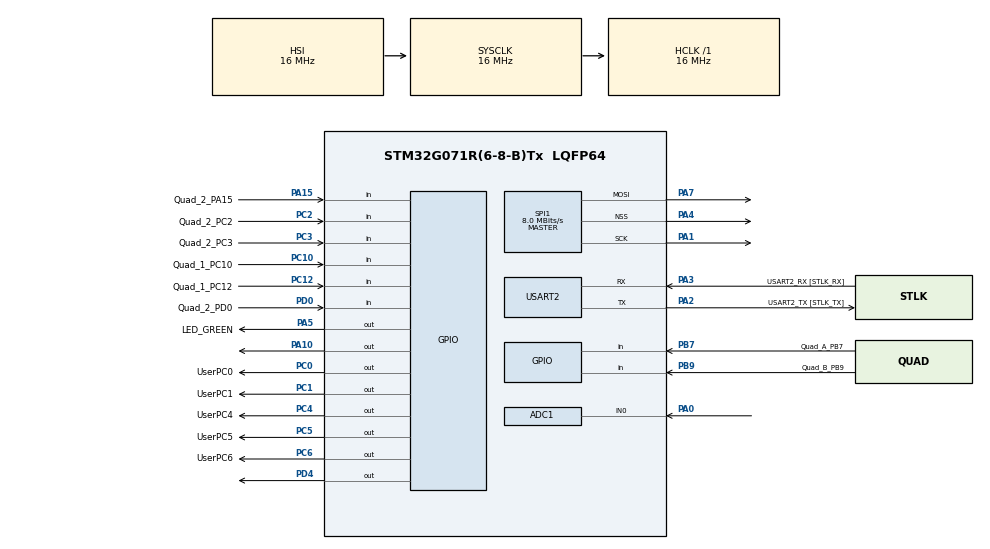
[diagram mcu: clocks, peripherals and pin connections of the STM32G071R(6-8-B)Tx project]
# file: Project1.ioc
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ADC1.Channel-0\#ChannelRegularConversion=ADC_CHANNEL_0
ADC1.NbrOfConversionFlag=1
ADC1.Rank-0\#ChannelRegularConversion=1
ADC1.SamplingTime-0\#ChannelRegularConversion=ADC_SAMPLINGTIME_COMMON_1
ADC1.SelectedChannel=ADC_CHANNEL_0
ADC1.master=1
Mcu.Family=STM32G0
Mcu.Name=STM32G071R(6-8-B)Tx
Mcu.Package=LQFP64
NVIC.TIM16_IRQn=true\:0\:0\:false\:false\:true\:true\:true\:true
NVIC.TIM17_IRQn=true\:0\:0\:false\:false\:true\:true\:true\:true
PA0.Mode=IN0
PA0.Signal=ADC1_IN0
PA1.Mode=TX_Only_Simplex_Unidirect_Master
PA1.Signal=SPI1_SCK
PA10.Signal=GPIO_Output
PA13.GPIO_Label=TMS
PA13.Mode=Serial_Wire
PA13.Signal=SYS_SWDIO
PA14-BOOT0.Mode=Serial_Wire
PA14-BOOT0.Signal=SYS_SWCLK
PA15.GPIO_Label=Quad_2_PA15
PA15.Signal=GPIO_Input
PA2.GPIO_Label=USART2_TX [STLK_TX]
PA2.GPIO_PuPd=GPIO_PULLUP
PA2.Mode=Asynchronous
PA2.Signal=USART2_TX
PA3.GPIO_Label=USART2_RX [STLK_RX]
PA3.GPIO_PuPd=GPIO_PULLUP
PA3.Mode=Asynchronous
PA3.Signal=USART2_RX
PA4.Mode=NSS_Signal_Hard_Output
PA4.Signal=SPI1_NSS
PA5.GPIO_Label=LED_GREEN
PA5.GPIO_Speed=GPIO_SPEED_FREQ_HIGH
PA5.Signal=GPIO_Output
PA7.Mode=TX_Only_Simplex_Unidirect_Master
PA7.Signal=SPI1_MOSI
PB7.GPIO_Label=Quad_A_PB7
PB7.GPIO_PuPd=GPIO_PULLUP
PB7.Signal=GPIO_Input
PB9.GPIO_Label=Quad_B_PB9
PB9.GPIO_PuPd=GPIO_PULLUP
PB9.Signal=GPIO_Input
PC0.GPIO_Label=UserPC0
PC0.Signal=GPIO_Output
PC1.GPIO_Label=UserPC1
PC1.Signal=GPIO_Output
PC10.GPIO_Label=Quad_1_PC10
PC10.GPIO_PuPd=GPIO_PULLUP
PC10.Signal=GPIO_Input
PC12.GPIO_Label=Quad_1_PC12
PC12.GPIO_PuPd=GPIO_PULLUP
PC12.Signal=GPIO_Input
PC13.Mode=SYS_WakeUp1
PC13.Signal=SYS_WKUP2
PC14-OSC32_IN\ (PC14).Mode=LSE-External-Oscillator
PC14-OSC32_IN\ (PC14).Signal=RCC_OSC32_IN
PC15-OSC32_OUT\ (PC15).Mode=LSE-External-Oscillator
PC15-OSC32_OUT\ (PC15).Signal=RCC_OSC32_OUT
PC2.GPIO_Label=Quad_2_PC2
PC2.GPIO_PuPd=GPIO_PULLUP
PC2.Signal=GPIO_Input
PC3.GPIO_Label=Quad_2_PC3
PC3.GPIO_PuPd=GPIO_PULLUP
PC3.Signal=GPIO_Input
PC4.GPIO_Label=UserPC4
PC4.Signal=GPIO_Output
PC5.GPIO_Label=UserPC5
PC5.Signal=GPIO_Output
PC6.GPIO_Label=UserPC6
PC6.Signal=GPIO_Output
PD0.GPIO_Label=Quad_2_PD0
PD0.Signal=GPIO_Input
PD4.Signal=GPIO_Output
PF0-OSC_IN\ (PF0).GPIO_Label=MCO
PF0-OSC_IN\ (PF0).Mode=HSE-External-Clock-Source
PF0-OSC_IN\ (PF0).Signal=RCC_OSC_IN
ProjectManager.HeapSize=0x200
ProjectManager.StackSize=0x400
ProjectManager.TargetToolchain=STM32CubeIDE
RCC.AHBFreq_Value=16000000
RCC.CortexFreq_Value=16000000
RCC.EXTERNAL_CLOCK_VALUE=12288000
RCC.HCLKFreq_Value=16000000
RCC.HSE_VALUE=8000000
RCC.HSI_VALUE=16000000
RCC.SYSCLKFreq_VALUE=16000000
RCC.VCOOutputFreq_Value=128000000
SPI1.BaudRatePrescaler=SPI_BAUDRATEPRESCALER_2
SPI1.CalculateBaudRate=8.0 MBits/s
SPI1.DataSize=SPI_DATASIZE_8BIT
SPI1.Direction=SPI_DIRECTION_2LINES
SPI1.Mode=SPI_MODE_MASTER
SPI1.VirtualNSS=VM_NSSHARD
SPI1.VirtualType=VM_MASTER
TIM16.Period=199
TIM16.Prescaler=2
TIM17.Period=7999
TIM17.Prescaler=1
USART2.VirtualMode-Asynchronous=VM_ASYNC
VP_TIM16_VS_ClockSourceINT.Mode=Enable_Timer
VP_TIM17_VS_ClockSourceINT.Mode=Enable_Timer
board=NUCLEO-G071RB

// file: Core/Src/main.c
/* USER CODE BEGIN Header */
/**
  ******************************************************************************
  * @file           : main.c
  * @brief          : Main program body
  ******************************************************************************
  * @attention
  *
  * Copyright (c) 2023 STMicroelectronics.
  * All rights reserved.
  *
  * This software is licensed under terms that can be found in the LICENSE file
  * in the root directory of this software component.
  * If no LICENSE file comes with this software, it is provided AS-IS.
  *
  ******************************************************************************
  */
/* USER CODE END Header */
#include "main.h"

/* USER CODE BEGIN Includes */
#include "cpp_main.h"
/* USER CODE END Includes */

ADC_HandleTypeDef hadc1;

SPI_HandleTypeDef hspi1;

TIM_HandleTypeDef htim16;
TIM_HandleTypeDef htim17;

UART_HandleTypeDef huart2;

void SystemClock_Config(void);
static void MX_GPIO_Init(void);
static void MX_USART2_UART_Init(void);
static void MX_TIM17_Init(void);
static void MX_ADC1_Init(void);
static void MX_TIM16_Init(void);
static void MX_SPI1_Init(void);

/* USER CODE BEGIN 0 */
//void HAL_TIM_PeriodElapsedCallback(TIM_HandleTypeDef *htim17){};

/* USER CODE END 0 */

int main(void)
{

  /* MCU Configuration--------------------------------------------------------*/

  /* Reset of all peripherals, Initializes the Flash interface and the Systick. */
  HAL_Init();

  /* Configure the system clock */
  SystemClock_Config();

  /* Initialize all configured peripherals */
  MX_GPIO_Init();
  MX_USART2_UART_Init();
  MX_TIM17_Init();
  MX_ADC1_Init();
  MX_TIM16_Init();
  MX_SPI1_Init();
  /* USER CODE BEGIN 2 */
  MX_TIM17_Init();

  /* USER CODE BEGIN 2 */
  /******************** Really Sean's code
  *********************/
  /*** Refers to "private variable" in line 43 symbol =
  htim17) ***/
  /*** Uses an ARM CMSIS function in the HAL framework
  ***/
  /*** Start the periodic timer now, immediately after
  init() ***/
  HAL_TIM_Base_Start_IT(&htim17);
  /*** Also initialize my knob-debounce FSM object, my
  queue ***/
  /*** object and my sample-timing object.
  ***/

  HAL_TIM_Base_Start_IT(&htim16);
  //HAL_ADC_Start_IT(&hadc1);

  /* USER CODE END 2 */

  /* Infinite loop */
  /* USER CODE BEGIN WHILE */
  do_cpp_loop();

  while (1)
  {
    /* USER CODE END WHILE */

  }
}

void SystemClock_Config(void)
{
  RCC_OscInitTypeDef RCC_OscInitStruct = {0};
  RCC_ClkInitTypeDef RCC_ClkInitStruct = {0};

  /** Configure the main internal regulator output voltage
  */
  HAL_PWREx_ControlVoltageScaling(PWR_REGULATOR_VOLTAGE_SCALE1);

  /** Initializes the RCC Oscillators according to the specified parameters
  * in the RCC_OscInitTypeDef structure.
  */
  RCC_OscInitStruct.OscillatorType = RCC_OSCILLATORTYPE_HSI;
  RCC_OscInitStruct.HSIState = RCC_HSI_ON;
  RCC_OscInitStruct.HSIDiv = RCC_HSI_DIV1;
  RCC_OscInitStruct.HSICalibrationValue = RCC_HSICALIBRATION_DEFAULT;
  RCC_OscInitStruct.PLL.PLLState = RCC_PLL_NONE;
  if (HAL_RCC_OscConfig(&RCC_OscInitStruct) != HAL_OK)
  {
    Error_Handler();
  }

  /** Initializes the CPU, AHB and APB buses clocks
  */
  RCC_ClkInitStruct.ClockType = RCC_CLOCKTYPE_HCLK|RCC_CLOCKTYPE_SYSCLK
                              |RCC_CLOCKTYPE_PCLK1;
  RCC_ClkInitStruct.SYSCLKSource = RCC_SYSCLKSOURCE_HSI;
  RCC_ClkInitStruct.AHBCLKDivider = RCC_SYSCLK_DIV1;
  RCC_ClkInitStruct.APB1CLKDivider = RCC_HCLK_DIV1;

  if (HAL_RCC_ClockConfig(&RCC_ClkInitStruct, FLASH_LATENCY_0) != HAL_OK)
  {
    Error_Handler();
  }
}

static void MX_ADC1_Init(void)
{

  ADC_ChannelConfTypeDef sConfig = {0};

  /** Configure the global features of the ADC (Clock, Resolution, Data Alignment and number of conversion)
  */
  hadc1.Instance = ADC1;
  hadc1.Init.ClockPrescaler = ADC_CLOCK_SYNC_PCLK_DIV2;
  hadc1.Init.Resolution = ADC_RESOLUTION_12B;
  hadc1.Init.DataAlign = ADC_DATAALIGN_RIGHT;
  hadc1.Init.ScanConvMode = ADC_SCAN_DISABLE;
  hadc1.Init.EOCSelection = ADC_EOC_SINGLE_CONV;
  hadc1.Init.LowPowerAutoWait = DISABLE;
  hadc1.Init.LowPowerAutoPowerOff = DISABLE;
  hadc1.Init.ContinuousConvMode = DISABLE;
  hadc1.Init.NbrOfConversion = 1;
  hadc1.Init.DiscontinuousConvMode = DISABLE;
  hadc1.Init.ExternalTrigConv = ADC_SOFTWARE_START;
  hadc1.Init.ExternalTrigConvEdge = ADC_EXTERNALTRIGCONVEDGE_NONE;
  hadc1.Init.DMAContinuousRequests = DISABLE;
  hadc1.Init.Overrun = ADC_OVR_DATA_PRESERVED;
  hadc1.Init.SamplingTimeCommon1 = ADC_SAMPLETIME_1CYCLE_5;
  hadc1.Init.SamplingTimeCommon2 = ADC_SAMPLETIME_1CYCLE_5;
  hadc1.Init.OversamplingMode = DISABLE;
  hadc1.Init.TriggerFrequencyMode = ADC_TRIGGER_FREQ_HIGH;
  if (HAL_ADC_Init(&hadc1) != HAL_OK)
  {
    Error_Handler();
  }

  /** Configure Regular Channel
  */
  sConfig.Channel = ADC_CHANNEL_0;
  sConfig.Rank = ADC_REGULAR_RANK_1;
  sConfig.SamplingTime = ADC_SAMPLINGTIME_COMMON_1;
  if (HAL_ADC_ConfigChannel(&hadc1, &sConfig) != HAL_OK)
  {
    Error_Handler();
  }

}

static void MX_SPI1_Init(void)
{

  /* SPI1 parameter configuration*/
  hspi1.Instance = SPI1;
  hspi1.Init.Mode = SPI_MODE_MASTER;
  hspi1.Init.Direction = SPI_DIRECTION_2LINES;
  hspi1.Init.DataSize = SPI_DATASIZE_8BIT;
  hspi1.Init.CLKPolarity = SPI_POLARITY_LOW;
  hspi1.Init.CLKPhase = SPI_PHASE_1EDGE;
  hspi1.Init.NSS = SPI_NSS_HARD_OUTPUT;
  hspi1.Init.BaudRatePrescaler = SPI_BAUDRATEPRESCALER_2;
  hspi1.Init.FirstBit = SPI_FIRSTBIT_MSB;
  hspi1.Init.TIMode = SPI_TIMODE_DISABLE;
  hspi1.Init.CRCCalculation = SPI_CRCCALCULATION_DISABLE;
  hspi1.Init.CRCPolynomial = 7;
  hspi1.Init.CRCLength = SPI_CRC_LENGTH_DATASIZE;
  hspi1.Init.NSSPMode = SPI_NSS_PULSE_ENABLE;
  if (HAL_SPI_Init(&hspi1) != HAL_OK)
  {
    Error_Handler();
  }

}

static void MX_TIM16_Init(void)
{

  htim16.Instance = TIM16;
  htim16.Init.Prescaler = 2;
  htim16.Init.CounterMode = TIM_COUNTERMODE_UP;
  htim16.Init.Period = 199;
  htim16.Init.ClockDivision = TIM_CLOCKDIVISION_DIV1;
  htim16.Init.RepetitionCounter = 0;
  htim16.Init.AutoReloadPreload = TIM_AUTORELOAD_PRELOAD_DISABLE;
  if (HAL_TIM_Base_Init(&htim16) != HAL_OK)
  {
    Error_Handler();
  }

}

static void MX_TIM17_Init(void)
{

  htim17.Instance = TIM17;
  htim17.Init.Prescaler = 1;
  htim17.Init.CounterMode = TIM_COUNTERMODE_UP;
  htim17.Init.Period = 7999;
  htim17.Init.ClockDivision = TIM_CLOCKDIVISION_DIV1;
  htim17.Init.RepetitionCounter = 0;
  htim17.Init.AutoReloadPreload = TIM_AUTORELOAD_PRELOAD_DISABLE;
  if (HAL_TIM_Base_Init(&htim17) != HAL_OK)
  {
    Error_Handler();
  }

}

static void MX_USART2_UART_Init(void)
{

  huart2.Instance = USART2;
  huart2.Init.BaudRate = 115200;
  huart2.Init.WordLength = UART_WORDLENGTH_8B;
  huart2.Init.StopBits = UART_STOPBITS_1;
  huart2.Init.Parity = UART_PARITY_NONE;
  huart2.Init.Mode = UART_MODE_TX_RX;
  huart2.Init.HwFlowCtl = UART_HWCONTROL_NONE;
  huart2.Init.OverSampling = UART_OVERSAMPLING_16;
  huart2.Init.OneBitSampling = UART_ONE_BIT_SAMPLE_DISABLE;
  huart2.Init.ClockPrescaler = UART_PRESCALER_DIV1;
  huart2.AdvancedInit.AdvFeatureInit = UART_ADVFEATURE_NO_INIT;
  if (HAL_UART_Init(&huart2) != HAL_OK)
  {
    Error_Handler();
  }
  if (HAL_UARTEx_SetTxFifoThreshold(&huart2, UART_TXFIFO_THRESHOLD_1_8) != HAL_OK)
  {
    Error_Handler();
  }
  if (HAL_UARTEx_SetRxFifoThreshold(&huart2, UART_RXFIFO_THRESHOLD_1_8) != HAL_OK)
  {
    Error_Handler();
  }
  if (HAL_UARTEx_DisableFifoMode(&huart2) != HAL_OK)
  {
    Error_Handler();
  }

}

static void MX_GPIO_Init(void)
{
  GPIO_InitTypeDef GPIO_InitStruct = {0};

  /* GPIO Ports Clock Enable */
  __HAL_RCC_GPIOC_CLK_ENABLE();
  __HAL_RCC_GPIOF_CLK_ENABLE();
  __HAL_RCC_GPIOA_CLK_ENABLE();
  __HAL_RCC_GPIOD_CLK_ENABLE();
  __HAL_RCC_GPIOB_CLK_ENABLE();

  /*Configure GPIO pin Output Level */
  HAL_GPIO_WritePin(GPIOC, UserPC0_Pin|UserPC1_Pin|UserPC4_Pin|UserPC5_Pin
                          |UserPC6_Pin, GPIO_PIN_RESET);

  /*Configure GPIO pin Output Level */
  HAL_GPIO_WritePin(GPIOA, LED_GREEN_Pin|GPIO_PIN_10, GPIO_PIN_RESET);

  /*Configure GPIO pin Output Level */
  HAL_GPIO_WritePin(GPIOD, GPIO_PIN_4, GPIO_PIN_RESET);

  /*Configure GPIO pins : Quad_1_PC12_Pin Quad_2_PC2_Pin Quad_2_PC3_Pin Quad_1_PC10_Pin */
  GPIO_InitStruct.Pin = Quad_1_PC12_Pin|Quad_2_PC2_Pin|Quad_2_PC3_Pin|Quad_1_PC10_Pin;
  GPIO_InitStruct.Mode = GPIO_MODE_INPUT;
  GPIO_InitStruct.Pull = GPIO_PULLUP;
  HAL_GPIO_Init(GPIOC, &GPIO_InitStruct);

  /*Configure GPIO pins : UserPC0_Pin UserPC1_Pin UserPC4_Pin UserPC5_Pin
                           UserPC6_Pin */
  GPIO_InitStruct.Pin = UserPC0_Pin|UserPC1_Pin|UserPC4_Pin|UserPC5_Pin
                          |UserPC6_Pin;
  GPIO_InitStruct.Mode = GPIO_MODE_OUTPUT_PP;
  GPIO_InitStruct.Pull = GPIO_NOPULL;
  GPIO_InitStruct.Speed = GPIO_SPEED_FREQ_LOW;
  HAL_GPIO_Init(GPIOC, &GPIO_InitStruct);

  /*Configure GPIO pin : LED_GREEN_Pin */
  GPIO_InitStruct.Pin = LED_GREEN_Pin;
  GPIO_InitStruct.Mode = GPIO_MODE_OUTPUT_PP;
  GPIO_InitStruct.Pull = GPIO_NOPULL;
  GPIO_InitStruct.Speed = GPIO_SPEED_FREQ_HIGH;
  HAL_GPIO_Init(LED_GREEN_GPIO_Port, &GPIO_InitStruct);

  /*Configure GPIO pin : PA10 */
  GPIO_InitStruct.Pin = GPIO_PIN_10;
  GPIO_InitStruct.Mode = GPIO_MODE_OUTPUT_PP;
  GPIO_InitStruct.Pull = GPIO_NOPULL;
  GPIO_InitStruct.Speed = GPIO_SPEED_FREQ_LOW;
  HAL_GPIO_Init(GPIOA, &GPIO_InitStruct);

  /*Configure GPIO pin : Quad_2_PA15_Pin */
  GPIO_InitStruct.Pin = Quad_2_PA15_Pin;
  GPIO_InitStruct.Mode = GPIO_MODE_INPUT;
  GPIO_InitStruct.Pull = GPIO_NOPULL;
  HAL_GPIO_Init(Quad_2_PA15_GPIO_Port, &GPIO_InitStruct);

  /*Configure GPIO pin : Quad_2_PD0_Pin */
  GPIO_InitStruct.Pin = Quad_2_PD0_Pin;
  GPIO_InitStruct.Mode = GPIO_MODE_INPUT;
  GPIO_InitStruct.Pull = GPIO_NOPULL;
  HAL_GPIO_Init(Quad_2_PD0_GPIO_Port, &GPIO_InitStruct);

  /*Configure GPIO pin : PD4 */
  GPIO_InitStruct.Pin = GPIO_PIN_4;
  GPIO_InitStruct.Mode = GPIO_MODE_OUTPUT_PP;
  GPIO_InitStruct.Pull = GPIO_NOPULL;
  GPIO_InitStruct.Speed = GPIO_SPEED_FREQ_LOW;
  HAL_GPIO_Init(GPIOD, &GPIO_InitStruct);

  /*Configure GPIO pins : Quad_A_PB7_Pin Quad_B_PB9_Pin */
  GPIO_InitStruct.Pin = Quad_A_PB7_Pin|Quad_B_PB9_Pin;
  GPIO_InitStruct.Mode = GPIO_MODE_INPUT;
  GPIO_InitStruct.Pull = GPIO_PULLUP;
  HAL_GPIO_Init(GPIOB, &GPIO_InitStruct);

}

void Error_Handler(void)
{
  __disable_irq();
  while (1)
  {
  }
}
